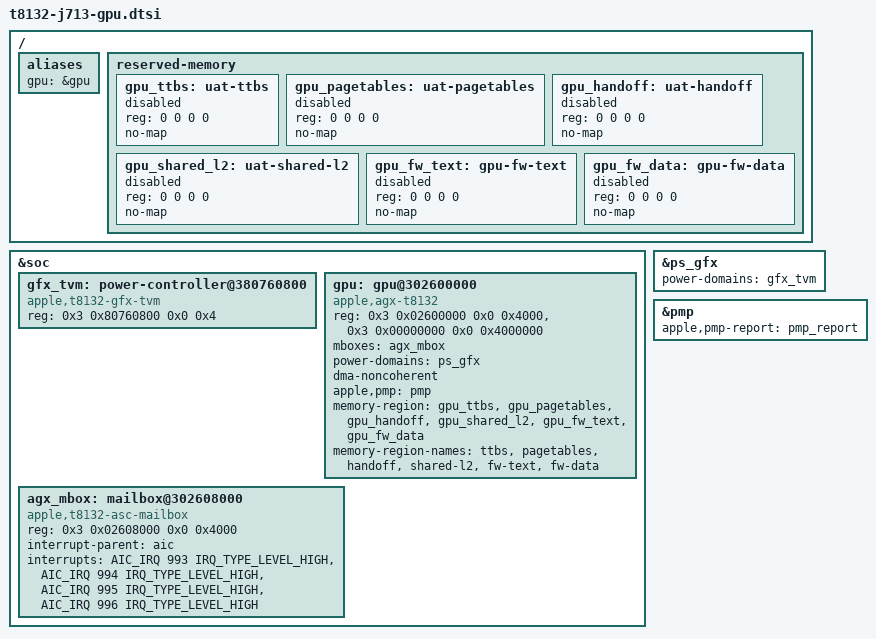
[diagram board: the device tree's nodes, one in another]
// SPDX-License-Identifier: GPL-2.0+ OR MIT
/*
 * Apple MacBook Air (13-inch, M4) G16 GPU resources.
 *
 * Node structure follows the J713 ADT; values match the cleanroom J713 live
 * device tree. The Rust Asahi G16 backend is loaded explicitly after the
 * native display and GFX TVM supplier are ready. m1n1 fills the inherited UAT
 * and firmware ranges below, sets them okay, and publishes the firmware
 * segment layout on the gpu node; Asahi validates this handoff before boot.
 *
 * Copyright The Asahi Linux Contributors
 */

/ {
	aliases {
		gpu = &gpu;
	};

	reserved-memory {
		gpu_ttbs: uat-ttbs {
			reg = <0 0 0 0>;
			no-map;
			status = "disabled";
		};

		gpu_pagetables: uat-pagetables {
			reg = <0 0 0 0>;
			no-map;
			status = "disabled";
		};

		gpu_handoff: uat-handoff {
			reg = <0 0 0 0>;
			no-map;
			status = "disabled";
		};

		gpu_shared_l2: uat-shared-l2 {
			reg = <0 0 0 0>;
			no-map;
			status = "disabled";
		};

		gpu_fw_text: gpu-fw-text {
			reg = <0 0 0 0>;
			no-map;
			status = "disabled";
		};

		gpu_fw_data: gpu-fw-data {
			reg = <0 0 0 0>;
			no-map;
			status = "disabled";
		};
	};
};

&soc {
	gfx_tvm: power-controller@380760800 {
		compatible = "apple,t8132-gfx-tvm";
		reg = <0x3 0x80760800 0x0 0x4>;
		#power-domain-cells = <0>;
	};

	gpu: gpu@302600000 {
		compatible = "apple,agx-t8132";
		reg = <0x3 0x02600000 0x0 0x4000>,
		      <0x3 0x00000000 0x0 0x4000000>;
		reg-names = "asc", "sgx";
		mboxes = <&agx_mbox>;
		power-domains = <&ps_gfx>;
		/* G16 is admitted on non-coherent DMA only. */
		dma-noncoherent;
		apple,pmp = <&pmp>;
		memory-region = <&gpu_ttbs>, <&gpu_pagetables>, <&gpu_handoff>,
				<&gpu_shared_l2>, <&gpu_fw_text>, <&gpu_fw_data>;
		memory-region-names = "ttbs", "pagetables", "handoff",
				      "shared-l2", "fw-text", "fw-data";
	};

	agx_mbox: mailbox@302608000 {
		/* ASCWrap v6 contains the same mailbox aperture used by ASC v4. */
		compatible = "apple,t8132-asc-mailbox", "apple,asc-mailbox-v4";
		reg = <0x3 0x02608000 0x0 0x4000>;
		interrupt-parent = <&aic>;
		interrupts = <AIC_IRQ 993 IRQ_TYPE_LEVEL_HIGH>,
			     <AIC_IRQ 994 IRQ_TYPE_LEVEL_HIGH>,
			     <AIC_IRQ 995 IRQ_TYPE_LEVEL_HIGH>,
			     <AIC_IRQ 996 IRQ_TYPE_LEVEL_HIGH>;
		interrupt-names = "send-empty", "send-not-empty",
				  "recv-empty", "recv-not-empty";
		#mbox-cells = <0>;
	};
};

/* The outer TVM gate is the parent of the GFX PMGR domain on J713. */
&ps_gfx {
	status = "okay";
	power-domains = <&gfx_tvm>;
};

/* The existing report provider owns readiness for shared PMP commands. */
&pmp {
	apple,pmp-report = <&pmp_report>;
};
